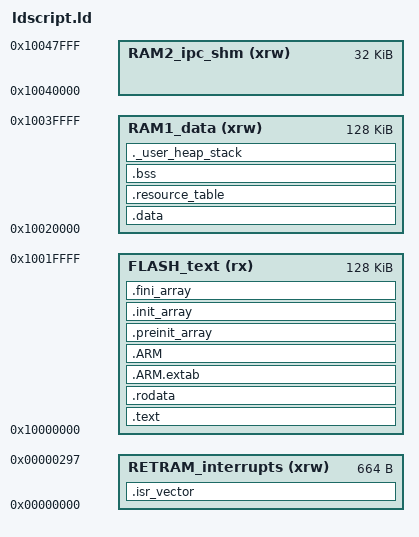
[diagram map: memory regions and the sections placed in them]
/**
 ******************************************************************************
 * @file      LinkerScript.ld
 * @author    Auto-generated by STM32CubeIDE
 * @brief     Linker script for STM32MP157xAC series
 *                      128Kbytes FLASH
 *                      128Kbytes RAM1
 *                      128Kbytes RAM2
 *
 *            Set heap size, stack size and stack location according
 *            to application requirements.
 *
 *            Set memory bank area and size if external memory is used
 ******************************************************************************
 * @attention
 *
 * <h2><center>&copy; Copyright (c) 2021 STMicroelectronics.
 * All rights reserved.</center></h2>
 *
 * This software component is licensed by ST under BSD 3-Clause license,
 * the "License"; You may not use this file except in compliance with the
 * License. You may obtain a copy of the License at:
 *                        opensource.org/licenses/BSD-3-Clause
 *
 ******************************************************************************
 */

/* Entry Point */
ENTRY(Reset_Handler)

/* Highest address of the user mode stack */
_estack = ORIGIN(RAM1_data) + LENGTH(RAM1_data);	/* end of "RAM1_data" Ram type memory */

_Min_Heap_Size = 0x200;	/* required amount of heap  */
_Min_Stack_Size = 0x400;	/* required amount of stack */

/* Memories definition */
MEMORY
{
  RETRAM_interrupts		(xrw)	: ORIGIN = 0x00000000,	LENGTH = 0x00000298
  FLASH_text		(rx)	: ORIGIN = 0x10000000,	LENGTH = 128K
  RAM1_data		(xrw)	: ORIGIN = 0x10020000,	LENGTH = 128K
  RAM2_ipc_shm		(xrw)	: ORIGIN = 0x10040000,	LENGTH = 0x00008000
}

 /* Symbols needed for OpenAMP to enable rpmsg */
__OPENAMP_region_start__  = ORIGIN(RAM2_ipc_shm);
__OPENAMP_region_end__ = ORIGIN(RAM2_ipc_shm)+LENGTH(RAM2_ipc_shm);

/* Sections */
SECTIONS
{
  /* The startup code into "RETRAM_interrupts" Ram type memory */
  .isr_vector :
  {
    . = ALIGN(4);
    KEEP(*(.isr_vector)) /* Startup code */
    . = ALIGN(4);
  } >RETRAM_interrupts

  /* The program code and other data into "FLASH_text" Rom type memory */
  .text :
  {
    . = ALIGN(4);
    *(.text)           /* .text sections (code) */
    *(.text*)          /* .text* sections (code) */
    *(.glue_7)         /* glue arm to thumb code */
    *(.glue_7t)        /* glue thumb to arm code */
    *(.eh_frame)

    KEEP (*(.init))
    KEEP (*(.fini))

    . = ALIGN(4);
    _etext = .;        /* define a global symbols at end of code */
  } >FLASH_text

  /* Constant data into "FLASH_text" Rom type memory */
  .rodata :
  {
    . = ALIGN(4);
    *(.rodata)         /* .rodata sections (constants, strings, etc.) */
    *(.rodata*)        /* .rodata* sections (constants, strings, etc.) */
    . = ALIGN(4);
  } >FLASH_text

  .ARM.extab   : {
  	. = ALIGN(4);
  	*(.ARM.extab* .gnu.linkonce.armextab.*)
  	. = ALIGN(4);
  } >FLASH_text

  .ARM : {
    . = ALIGN(4);
    __exidx_start = .;
    *(.ARM.exidx*)
    __exidx_end = .;
    . = ALIGN(4);
  } >FLASH_text

  .preinit_array     :
  {
    . = ALIGN(4);
    PROVIDE_HIDDEN (__preinit_array_start = .);
    KEEP (*(.preinit_array*))
    PROVIDE_HIDDEN (__preinit_array_end = .);
    . = ALIGN(4);
  } >FLASH_text

  .init_array :
  {
    . = ALIGN(4);
    PROVIDE_HIDDEN (__init_array_start = .);
    KEEP (*(SORT(.init_array.*)))
    KEEP (*(.init_array*))
    PROVIDE_HIDDEN (__init_array_end = .);
    . = ALIGN(4);
  } >FLASH_text

  .fini_array :
  {
    . = ALIGN(4);
    PROVIDE_HIDDEN (__fini_array_start = .);
    KEEP (*(SORT(.fini_array.*)))
    KEEP (*(.fini_array*))
    PROVIDE_HIDDEN (__fini_array_end = .);
    . = ALIGN(4);
  } >FLASH_text

  /* Used by the startup to initialize data */
  __DATA_ROM = .;
  _sidata = LOADADDR(.data);

  /* Initialized data sections into "RAM1_data" Ram type memory */
  .data :  AT(__DATA_ROM)
  {
    . = ALIGN(4);
    _sdata = .;        /* create a global symbol at data start */
    *(.data)           /* .data sections */
    *(.data*)          /* .data* sections */

    . = ALIGN(4);
    _edata = .;        /* define a global symbol at data end */
  } >RAM1_data

    __DATA_END = __DATA_ROM + (_edata - _sdata);
  text_end = ORIGIN(FLASH_text) + LENGTH(FLASH_text);
  ASSERT(__DATA_END <= text_end, "region FLASH_text overflowed with text and data")


  .resource_table :
  {
    . = ALIGN(4);
    KEEP (*(.resource_table*))
    . = ALIGN(4);
  } >RAM1_data

  /* Uninitialized data section into "RAM1_data" Ram type memory */
  . = ALIGN(4);
  .bss :
  {
    /* This is used by the startup in order to initialize the .bss section */
    _sbss = .;         /* define a global symbol at bss start */
    __bss_start__ = _sbss;
    *(.bss)
    *(.bss*)
    *(COMMON)

    . = ALIGN(4);
    _ebss = .;         /* define a global symbol at bss end */
    __bss_end__ = _ebss;
  } >RAM1_data

  /* User_heap_stack section, used to check that there is enough "RAM1_data" Ram  type memory left */
  ._user_heap_stack :
  {
    . = ALIGN(8);
    PROVIDE ( end = . );
    PROVIDE ( _end = . );
    . = . + _Min_Heap_Size;
    . = . + _Min_Stack_Size;
    . = ALIGN(8);
  } >RAM1_data

  /* Remove information from the compiler libraries */
  /DISCARD/ :
  {
    libc.a ( * )
    libm.a ( * )
    libgcc.a ( * )
  }

  .ARM.attributes 0 : { *(.ARM.attributes) }
}
